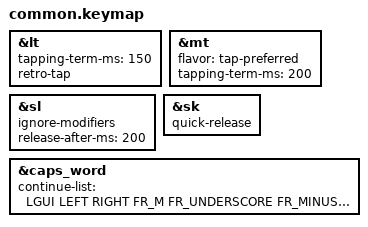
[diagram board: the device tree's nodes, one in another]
/*
 * Copyright (c) 2022 The ZMK Contributors
 *
 * SPDX-License-Identifier: MIT
 */

#define INVERT_HD 1

#include "keys_mac_fr.h"
#include <behaviors.dtsi>
#include <dt-bindings/zmk/bt.h>
#include <dt-bindings/zmk/keys.h>
#include <dt-bindings/zmk/outputs.h>

#include "zmk-helpers/helper.h"
#include "key_names.h"

#define SMB 1

#define ______  &trans


#define my_tapping_term 170
#define my_quick_tapping_term 112
#define my_ak_delay 1000

&lt {
    tapping-term-ms = <150>;
    retro-tap;
};
&mt {
    flavor = "tap-preferred";
    tapping-term-ms = <200>;
};

&sl { 
    ignore-modifiers; 
    release-after-ms = <200>;
};

&sk {
    quick-release;
};

&caps_word {
    continue-list = <LGUI LEFT RIGHT FR_M FR_UNDERSCORE FR_MINUS DELETE BACKSPACE>;
};

#include "my_helpers.dtsi"
#include "new_macros.dtsi"
#include "behaviors.dtsi"
#include "combos.dtsi"
#include "layers.dtsi"
